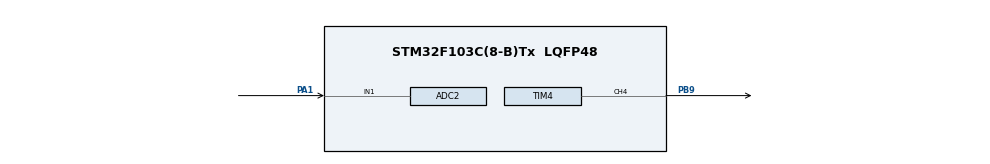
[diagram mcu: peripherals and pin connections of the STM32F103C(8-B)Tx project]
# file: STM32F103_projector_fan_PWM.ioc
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ADC2.Channel-8\#ChannelRegularConversion=ADC_CHANNEL_1
ADC2.NbrOfConversionFlag=1
ADC2.Rank-8\#ChannelRegularConversion=1
ADC2.SamplingTime-8\#ChannelRegularConversion=ADC_SAMPLETIME_1CYCLE_5
Mcu.Family=STM32F1
Mcu.Name=STM32F103C(8-B)Tx
Mcu.Package=LQFP48
NVIC.PriorityGroup=NVIC_PRIORITYGROUP_4
PA1.Signal=ADCx_IN1
PA13.Mode=Serial_Wire
PA13.Signal=SYS_JTMS-SWDIO
PA14.Mode=Serial_Wire
PA14.Signal=SYS_JTCK-SWCLK
PB9.Signal=S_TIM4_CH4
PD0-OSC_IN.Mode=HSE-External-Oscillator
PD0-OSC_IN.Signal=RCC_OSC_IN
PD1-OSC_OUT.Mode=HSE-External-Oscillator
PD1-OSC_OUT.Signal=RCC_OSC_OUT
ProjectManager.HeapSize=0x200
ProjectManager.StackSize=0x400
ProjectManager.TargetToolchain=TrueSTUDIO
RCC.APB1Freq_Value=8000000
RCC.APB2Freq_Value=8000000
SH.ADCx_IN1.0=ADC2_IN1,IN1
SH.S_TIM4_CH4.0=TIM4_CH4,PWM Generation4 CH4
TIM4.Channel-PWM\ Generation4\ CH4=TIM_CHANNEL_4
TIM4.ClockDivision=TIM_CLOCKDIVISION_DIV1
TIM4.Period=320
board=custom

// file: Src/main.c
/* USER CODE BEGIN Header */
/**
  ******************************************************************************
  * @file           : main.c
  * @brief          : Main program body
  ******************************************************************************
  ** This notice applies to any and all portions of this file
  * that are not between comment pairs USER CODE BEGIN and
  * USER CODE END. Other portions of this file, whether
  * inserted by the user or by software development tools
  * are owned by their respective copyright owners.
  *
  * COPYRIGHT(c) 2019 STMicroelectronics
  *
  * Redistribution and use in source and binary forms, with or without modification,
  * are permitted provided that the following conditions are met:
  *   1. Redistributions of source code must retain the above copyright notice,
  *      this list of conditions and the following disclaimer.
  *   2. Redistributions in binary form must reproduce the above copyright notice,
  *      this list of conditions and the following disclaimer in the documentation
  *      and/or other materials provided with the distribution.
  *   3. Neither the name of STMicroelectronics nor the names of its contributors
  *      may be used to endorse or promote products derived from this software
  *      without specific prior written permission.
  *
  * THIS SOFTWARE IS PROVIDED BY THE COPYRIGHT HOLDERS AND CONTRIBUTORS "AS IS"
  * AND ANY EXPRESS OR IMPLIED WARRANTIES, INCLUDING, BUT NOT LIMITED TO, THE
  * IMPLIED WARRANTIES OF MERCHANTABILITY AND FITNESS FOR A PARTICULAR PURPOSE ARE
  * DISCLAIMED. IN NO EVENT SHALL THE COPYRIGHT HOLDER OR CONTRIBUTORS BE LIABLE
  * FOR ANY DIRECT, INDIRECT, INCIDENTAL, SPECIAL, EXEMPLARY, OR CONSEQUENTIAL
  * DAMAGES (INCLUDING, BUT NOT LIMITED TO, PROCUREMENT OF SUBSTITUTE GOODS OR
  * SERVICES; LOSS OF USE, DATA, OR PROFITS; OR BUSINESS INTERRUPTION) HOWEVER
  * CAUSED AND ON ANY THEORY OF LIABILITY, WHETHER IN CONTRACT, STRICT LIABILITY,
  * OR TORT (INCLUDING NEGLIGENCE OR OTHERWISE) ARISING IN ANY WAY OUT OF THE USE
  * OF THIS SOFTWARE, EVEN IF ADVISED OF THE POSSIBILITY OF SUCH DAMAGE.
  *
  ******************************************************************************
  */
/* USER CODE END Header */

#include "main.h"

ADC_HandleTypeDef hadc2;

TIM_HandleTypeDef htim4;

void SystemClock_Config(void);
static void MX_GPIO_Init(void);
static void MX_ADC2_Init(void);
static void MX_TIM4_Init(void);

int main(void)
{
  /* USER CODE BEGIN 1 */
int PWM = 50;
  /* USER CODE END 1 */

  /* MCU Configuration--------------------------------------------------------*/

  /* Reset of all peripherals, Initializes the Flash interface and the Systick. */
  HAL_Init();

  /* Configure the system clock */
  SystemClock_Config();

  /* Initialize all configured peripherals */
  MX_GPIO_Init();
  MX_ADC2_Init();
  MX_TIM4_Init();
  /* USER CODE BEGIN 2 */
HAL_TIM_PWM_Start(&htim4, TIM_CHANNEL_4);
HAL_ADC_Start(&hadc2);
  /* USER CODE END 2 */

  /* Infinite loop */
  while (1)
  {

    /* USER CODE BEGIN 3 */
	  //htim4.Instance->CCR1 = PWM;
	  //HAL_ADC_PollForConversion(&hadc2,100);
	  HAL_ADC_Stop(&hadc2);
	  HAL_ADC_Start(&hadc2);

	  PWM = HAL_ADC_GetValue(&hadc2) / 13;
	//  __HAL_TIM_SetCompare(&htim4, TIM_CHANNEL_4, PWM);
	  __HAL_TIM_SET_COMPARE(&htim4, TIM_CHANNEL_4, PWM);

  }
  /* USER CODE END 3 */
}

void SystemClock_Config(void)
{
  RCC_OscInitTypeDef RCC_OscInitStruct = {0};
  RCC_ClkInitTypeDef RCC_ClkInitStruct = {0};
  RCC_PeriphCLKInitTypeDef PeriphClkInit = {0};

  /**Initializes the CPU, AHB and APB busses clocks
  */
  RCC_OscInitStruct.OscillatorType = RCC_OSCILLATORTYPE_HSI;
  RCC_OscInitStruct.HSIState = RCC_HSI_ON;
  RCC_OscInitStruct.HSICalibrationValue = RCC_HSICALIBRATION_DEFAULT;
  RCC_OscInitStruct.PLL.PLLState = RCC_PLL_NONE;
  if (HAL_RCC_OscConfig(&RCC_OscInitStruct) != HAL_OK)
  {
    Error_Handler();
  }
  /**Initializes the CPU, AHB and APB busses clocks
  */
  RCC_ClkInitStruct.ClockType = RCC_CLOCKTYPE_HCLK|RCC_CLOCKTYPE_SYSCLK
                              |RCC_CLOCKTYPE_PCLK1|RCC_CLOCKTYPE_PCLK2;
  RCC_ClkInitStruct.SYSCLKSource = RCC_SYSCLKSOURCE_HSI;
  RCC_ClkInitStruct.AHBCLKDivider = RCC_SYSCLK_DIV1;
  RCC_ClkInitStruct.APB1CLKDivider = RCC_HCLK_DIV1;
  RCC_ClkInitStruct.APB2CLKDivider = RCC_HCLK_DIV1;

  if (HAL_RCC_ClockConfig(&RCC_ClkInitStruct, FLASH_LATENCY_0) != HAL_OK)
  {
    Error_Handler();
  }
  PeriphClkInit.PeriphClockSelection = RCC_PERIPHCLK_ADC;
  PeriphClkInit.AdcClockSelection = RCC_ADCPCLK2_DIV2;
  if (HAL_RCCEx_PeriphCLKConfig(&PeriphClkInit) != HAL_OK)
  {
    Error_Handler();
  }
}

static void MX_ADC2_Init(void)
{

  ADC_ChannelConfTypeDef sConfig = {0};

  /**Common config
  */
  hadc2.Instance = ADC2;
  hadc2.Init.ScanConvMode = ADC_SCAN_DISABLE;
  hadc2.Init.ContinuousConvMode = DISABLE;
  hadc2.Init.DiscontinuousConvMode = DISABLE;
  hadc2.Init.ExternalTrigConv = ADC_SOFTWARE_START;
  hadc2.Init.DataAlign = ADC_DATAALIGN_RIGHT;
  hadc2.Init.NbrOfConversion = 1;
  if (HAL_ADC_Init(&hadc2) != HAL_OK)
  {
    Error_Handler();
  }
  /**Configure Regular Channel
  */
  sConfig.Channel = ADC_CHANNEL_1;
  sConfig.Rank = ADC_REGULAR_RANK_1;
  sConfig.SamplingTime = ADC_SAMPLETIME_1CYCLE_5;
  if (HAL_ADC_ConfigChannel(&hadc2, &sConfig) != HAL_OK)
  {
    Error_Handler();
  }

}

static void MX_TIM4_Init(void)
{

  TIM_MasterConfigTypeDef sMasterConfig = {0};
  TIM_OC_InitTypeDef sConfigOC = {0};

  htim4.Instance = TIM4;
  htim4.Init.Prescaler = 0;
  htim4.Init.CounterMode = TIM_COUNTERMODE_UP;
  htim4.Init.Period = 320;
  htim4.Init.ClockDivision = TIM_CLOCKDIVISION_DIV1;
  htim4.Init.AutoReloadPreload = TIM_AUTORELOAD_PRELOAD_DISABLE;
  if (HAL_TIM_PWM_Init(&htim4) != HAL_OK)
  {
    Error_Handler();
  }
  sMasterConfig.MasterOutputTrigger = TIM_TRGO_RESET;
  sMasterConfig.MasterSlaveMode = TIM_MASTERSLAVEMODE_DISABLE;
  if (HAL_TIMEx_MasterConfigSynchronization(&htim4, &sMasterConfig) != HAL_OK)
  {
    Error_Handler();
  }
  sConfigOC.OCMode = TIM_OCMODE_PWM1;
  sConfigOC.Pulse = 160;
  sConfigOC.OCPolarity = TIM_OCPOLARITY_HIGH;
  sConfigOC.OCFastMode = TIM_OCFAST_DISABLE;
  if (HAL_TIM_PWM_ConfigChannel(&htim4, &sConfigOC, TIM_CHANNEL_4) != HAL_OK)
  {
    Error_Handler();
  }
  HAL_TIM_MspPostInit(&htim4);

}

static void MX_GPIO_Init(void)
{

  /* GPIO Ports Clock Enable */
  __HAL_RCC_GPIOD_CLK_ENABLE();
  __HAL_RCC_GPIOA_CLK_ENABLE();
  __HAL_RCC_GPIOB_CLK_ENABLE();

}

void Error_Handler(void)
{
}

/************************ (C) COPYRIGHT STMicroelectronics *****END OF FILE****/
